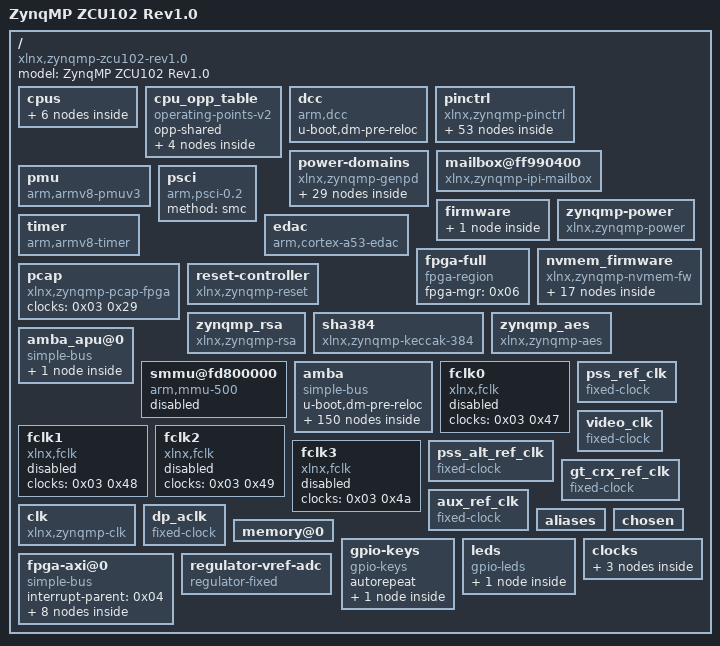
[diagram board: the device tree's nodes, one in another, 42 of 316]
/dts-v1/;

/ {
	compatible = "xlnx,zynqmp-zcu102-rev1.0\0xlnx,zynqmp-zcu102\0xlnx,zynqmp";
	#address-cells = <0x02>;
	#size-cells = <0x02>;
	model = "ZynqMP ZCU102 Rev1.0";

	cpus {
		#address-cells = <0x01>;
		#size-cells = <0x00>;

		cpu@0 {
			compatible = "arm,cortex-a53\0arm,armv8";
			device_type = "cpu";
			enable-method = "psci";
			operating-points-v2 = <0x01>;
			reg = <0x00>;
			cpu-idle-states = <0x02>;
			clocks = <0x03 0x0a>;
		};

		cpu@1 {
			compatible = "arm,cortex-a53\0arm,armv8";
			device_type = "cpu";
			enable-method = "psci";
			reg = <0x01>;
			operating-points-v2 = <0x01>;
			cpu-idle-states = <0x02>;
		};

		cpu@2 {
			compatible = "arm,cortex-a53\0arm,armv8";
			device_type = "cpu";
			enable-method = "psci";
			reg = <0x02>;
			operating-points-v2 = <0x01>;
			cpu-idle-states = <0x02>;
		};

		cpu@3 {
			compatible = "arm,cortex-a53\0arm,armv8";
			device_type = "cpu";
			enable-method = "psci";
			reg = <0x03>;
			operating-points-v2 = <0x01>;
			cpu-idle-states = <0x02>;
		};

		idle-states {
			entry-method = "arm,psci";

			cpu-sleep-0 {
				compatible = "arm,idle-state";
				arm,psci-suspend-param = <0x40000000>;
				local-timer-stop;
				entry-latency-us = <0x12c>;
				exit-latency-us = <0x258>;
				min-residency-us = <0x2710>;
				linux,phandle = <0x02>;
				phandle = <0x02>;
			};
		};
	};

	cpu_opp_table {
		compatible = "operating-points-v2";
		opp-shared;
		linux,phandle = <0x01>;
		phandle = <0x01>;

		opp00 {
			opp-hz = <0x00 0x47868bf4>;
			opp-microvolt = <0xf4240>;
			clock-latency-ns = <0x7a120>;
		};

		opp01 {
			opp-hz = <0x00 0x23c345fa>;
			opp-microvolt = <0xf4240>;
			clock-latency-ns = <0x7a120>;
		};

		opp02 {
			opp-hz = <0x00 0x17d783fc>;
			opp-microvolt = <0xf4240>;
			clock-latency-ns = <0x7a120>;
		};

		opp03 {
			opp-hz = <0x00 0x11e1a2fd>;
			opp-microvolt = <0xf4240>;
			clock-latency-ns = <0x7a120>;
		};
	};

	dcc {
		compatible = "arm,dcc";
		status = "okay";
		u-boot,dm-pre-reloc;
	};

	pinctrl {
		compatible = "xlnx,zynqmp-pinctrl";
		status = "okay";

		i2c0-default {
			linux,phandle = <0x18>;
			phandle = <0x18>;

			mux {
				groups = "i2c0_3_grp";
				function = "i2c0";
			};

			conf {
				groups = "i2c0_3_grp";
				bias-pull-up;
				slew-rate = <0x01>;
				io-standard = <0x01>;
			};
		};

		i2c0-gpio {
			linux,phandle = <0x19>;
			phandle = <0x19>;

			mux {
				groups = "gpio0_14_grp\0gpio0_15_grp";
				function = "gpio0";
			};

			conf {
				groups = "gpio0_14_grp\0gpio0_15_grp";
				slew-rate = <0x01>;
				io-standard = <0x01>;
			};
		};

		i2c1-default {
			linux,phandle = <0x1c>;
			phandle = <0x1c>;

			mux {
				groups = "i2c1_4_grp";
				function = "i2c1";
			};

			conf {
				groups = "i2c1_4_grp";
				bias-pull-up;
				slew-rate = <0x01>;
				io-standard = <0x01>;
			};
		};

		i2c1-gpio {
			linux,phandle = <0x1d>;
			phandle = <0x1d>;

			mux {
				groups = "gpio0_16_grp\0gpio0_17_grp";
				function = "gpio0";
			};

			conf {
				groups = "gpio0_16_grp\0gpio0_17_grp";
				slew-rate = <0x01>;
				io-standard = <0x01>;
			};
		};

		uart0-default {
			linux,phandle = <0x32>;
			phandle = <0x32>;

			mux {
				groups = "uart0_4_grp";
				function = "uart0";
			};

			conf {
				groups = "uart0_4_grp";
				slew-rate = <0x01>;
				io-standard = <0x01>;
			};

			conf-rx {
				pins = "MIO18";
				bias-high-impedance;
			};

			conf-tx {
				pins = "MIO19";
				bias-disable;
			};
		};

		uart1-default {
			linux,phandle = <0x34>;
			phandle = <0x34>;

			mux {
				groups = "uart1_5_grp";
				function = "uart1";
			};

			conf {
				groups = "uart1_5_grp";
				slew-rate = <0x01>;
				io-standard = <0x01>;
			};

			conf-rx {
				pins = "MIO21";
				bias-high-impedance;
			};

			conf-tx {
				pins = "MIO20";
				bias-disable;
			};
		};

		usb0-default {
			linux,phandle = <0x36>;
			phandle = <0x36>;

			mux {
				groups = "usb0_0_grp";
				function = "usb0";
			};

			conf {
				groups = "usb0_0_grp";
				slew-rate = <0x01>;
				io-standard = <0x01>;
			};

			conf-rx {
				pins = "MIO52\0MIO53\0MIO55";
				bias-high-impedance;
			};

			conf-tx {
				pins = "MIO54\0MIO56\0MIO57\0MIO58\0MIO59\0MIO60\0MIO61\0MIO62\0MIO63";
				bias-disable;
			};
		};

		gem3-default {
			linux,phandle = <0x14>;
			phandle = <0x14>;

			mux {
				function = "ethernet3";
				groups = "ethernet3_0_grp";
			};

			conf {
				groups = "ethernet3_0_grp";
				slew-rate = <0x01>;
				io-standard = <0x01>;
			};

			conf-rx {
				pins = "MIO70\0MIO71\0MIO72\0MIO73\0MIO74\0MIO75";
				bias-high-impedance;
				low-power-disable;
			};

			conf-tx {
				pins = "MIO64\0MIO65\0MIO66\0MIO67\0MIO68\0MIO69";
				bias-disable;
				low-power-enable;
			};

			mux-mdio {
				function = "mdio3";
				groups = "mdio3_0_grp";
			};

			conf-mdio {
				groups = "mdio3_0_grp";
				slew-rate = <0x01>;
				io-standard = <0x01>;
				bias-disable;
			};
		};

		can1-default {
			linux,phandle = <0x09>;
			phandle = <0x09>;

			mux {
				function = "can1";
				groups = "can1_6_grp";
			};

			conf {
				groups = "can1_6_grp";
				slew-rate = <0x01>;
				io-standard = <0x01>;
			};

			conf-rx {
				pins = "MIO25";
				bias-high-impedance;
			};

			conf-tx {
				pins = "MIO24";
				bias-disable;
			};
		};

		sdhci1-default {
			linux,phandle = <0x28>;
			phandle = <0x28>;

			mux {
				groups = "sdio1_0_grp";
				function = "sdio1";
			};

			conf {
				groups = "sdio1_0_grp";
				slew-rate = <0x01>;
				io-standard = <0x01>;
				bias-disable;
			};

			mux-cd {
				groups = "sdio1_cd_0_grp";
				function = "sdio1_cd";
			};

			conf-cd {
				groups = "sdio1_cd_0_grp";
				bias-high-impedance;
				bias-pull-up;
				slew-rate = <0x01>;
				io-standard = <0x01>;
			};

			mux-wp {
				groups = "sdio1_wp_0_grp";
				function = "sdio1_wp";
			};

			conf-wp {
				groups = "sdio1_wp_0_grp";
				bias-high-impedance;
				bias-pull-up;
				slew-rate = <0x01>;
				io-standard = <0x01>;
			};
		};

		gpio-default {
			linux,phandle = <0x16>;
			phandle = <0x16>;

			mux-sw {
				function = "gpio0";
				groups = "gpio0_22_grp\0gpio0_23_grp";
			};

			conf-sw {
				groups = "gpio0_22_grp\0gpio0_23_grp";
				slew-rate = <0x01>;
				io-standard = <0x01>;
			};

			mux-msp {
				function = "gpio0";
				groups = "gpio0_13_grp\0gpio0_38_grp";
			};

			conf-msp {
				groups = "gpio0_13_grp\0gpio0_38_grp";
				slew-rate = <0x01>;
				io-standard = <0x01>;
			};

			conf-pull-up {
				pins = "MIO22\0MIO23";
				bias-pull-up;
			};

			conf-pull-none {
				pins = "MIO13\0MIO38";
				bias-disable;
			};
		};
	};

	power-domains {
		compatible = "xlnx,zynqmp-genpd";

		pd-usb0 {
			#power-domain-cells = <0x00>;
			pd-id = <0x16>;
			linux,phandle = <0x35>;
			phandle = <0x35>;
		};

		pd-usb1 {
			#power-domain-cells = <0x00>;
			pd-id = <0x17>;
			linux,phandle = <0x38>;
			phandle = <0x38>;
		};

		pd-sata {
			#power-domain-cells = <0x00>;
			pd-id = <0x1c>;
			linux,phandle = <0x24>;
			phandle = <0x24>;
		};

		pd-spi0 {
			#power-domain-cells = <0x00>;
			pd-id = <0x23>;
			linux,phandle = <0x29>;
			phandle = <0x29>;
		};

		pd-spi1 {
			#power-domain-cells = <0x00>;
			pd-id = <0x24>;
			linux,phandle = <0x2c>;
			phandle = <0x2c>;
		};

		pd-uart0 {
			#power-domain-cells = <0x00>;
			pd-id = <0x21>;
			linux,phandle = <0x31>;
			phandle = <0x31>;
		};

		pd-uart1 {
			#power-domain-cells = <0x00>;
			pd-id = <0x22>;
			linux,phandle = <0x33>;
			phandle = <0x33>;
		};

		pd-eth0 {
			#power-domain-cells = <0x00>;
			pd-id = <0x1d>;
			linux,phandle = <0x0f>;
			phandle = <0x0f>;
		};

		pd-eth1 {
			#power-domain-cells = <0x00>;
			pd-id = <0x1e>;
			linux,phandle = <0x10>;
			phandle = <0x10>;
		};

		pd-eth2 {
			#power-domain-cells = <0x00>;
			pd-id = <0x1f>;
			linux,phandle = <0x11>;
			phandle = <0x11>;
		};

		pd-eth3 {
			#power-domain-cells = <0x00>;
			pd-id = <0x20>;
			linux,phandle = <0x12>;
			phandle = <0x12>;
		};

		pd-i2c0 {
			#power-domain-cells = <0x00>;
			pd-id = <0x25>;
			linux,phandle = <0x17>;
			phandle = <0x17>;
		};

		pd-i2c1 {
			#power-domain-cells = <0x00>;
			pd-id = <0x26>;
			linux,phandle = <0x1b>;
			phandle = <0x1b>;
		};

		pd-dp {
			#power-domain-cells = <0x00>;
			pd-id = <0x29>;
			linux,phandle = <0x39>;
			phandle = <0x39>;
		};

		pd-gdma {
			#power-domain-cells = <0x00>;
			pd-id = <0x2a>;
			linux,phandle = <0x0b>;
			phandle = <0x0b>;
		};

		pd-adma {
			#power-domain-cells = <0x00>;
			pd-id = <0x2b>;
			linux,phandle = <0x0d>;
			phandle = <0x0d>;
		};

		pd-ttc0 {
			#power-domain-cells = <0x00>;
			pd-id = <0x18>;
			linux,phandle = <0x2d>;
			phandle = <0x2d>;
		};

		pd-ttc1 {
			#power-domain-cells = <0x00>;
			pd-id = <0x19>;
			linux,phandle = <0x2e>;
			phandle = <0x2e>;
		};

		pd-ttc2 {
			#power-domain-cells = <0x00>;
			pd-id = <0x1a>;
			linux,phandle = <0x2f>;
			phandle = <0x2f>;
		};

		pd-ttc3 {
			#power-domain-cells = <0x00>;
			pd-id = <0x1b>;
			linux,phandle = <0x30>;
			phandle = <0x30>;
		};

		pd-sd0 {
			#power-domain-cells = <0x00>;
			pd-id = <0x27>;
			linux,phandle = <0x26>;
			phandle = <0x26>;
		};

		pd-sd1 {
			#power-domain-cells = <0x00>;
			pd-id = <0x28>;
			linux,phandle = <0x27>;
			phandle = <0x27>;
		};

		pd-nand {
			#power-domain-cells = <0x00>;
			pd-id = <0x2c>;
			linux,phandle = <0x0e>;
			phandle = <0x0e>;
		};

		pd-qspi {
			#power-domain-cells = <0x00>;
			pd-id = <0x2d>;
			linux,phandle = <0x21>;
			phandle = <0x21>;
		};

		pd-gpio {
			#power-domain-cells = <0x00>;
			pd-id = <0x2e>;
			linux,phandle = <0x15>;
			phandle = <0x15>;
		};

		pd-can0 {
			#power-domain-cells = <0x00>;
			pd-id = <0x2f>;
			linux,phandle = <0x07>;
			phandle = <0x07>;
		};

		pd-can1 {
			#power-domain-cells = <0x00>;
			pd-id = <0x30>;
			linux,phandle = <0x08>;
			phandle = <0x08>;
		};

		pd-pcie {
			#power-domain-cells = <0x00>;
			pd-id = <0x3b>;
			linux,phandle = <0x20>;
			phandle = <0x20>;
		};

		pd-gpu {
			#power-domain-cells = <0x00>;
			pd-id = <0x3a 0x14 0x15>;
			linux,phandle = <0x0c>;
			phandle = <0x0c>;
		};
	};

	mailbox@ff990400 {
		compatible = "xlnx,zynqmp-ipi-mailbox";
		reg = <0x00 0xff9905c0 0x00 0x20 0x00 0xff9905e0 0x00 0x20 0x00 0xff990e80 0x00 0x20 0x00 0xff990ea0 0x00 0x20>;
		reg-names = "local_request_region\0local_response_region\0remote_request_region\0remote_response_region";
		#mbox-cells = <0x01>;
		xlnx,ipi-ids = <0x00 0x04>;
		interrupt-parent = <0x04>;
		interrupts = <0x00 0x23 0x04>;
		linux,phandle = <0x05>;
		phandle = <0x05>;
	};

	pmu {
		compatible = "arm,armv8-pmuv3";
		interrupt-parent = <0x04>;
		interrupts = <0x00 0x8f 0x04 0x00 0x90 0x04 0x00 0x91 0x04 0x00 0x92 0x04>;
	};

	psci {
		compatible = "arm,psci-0.2";
		method = "smc";
	};

	firmware {

		zynqmp-firmware {
			compatible = "xlnx,zynqmp-firmware";
			method = "smc";
		};
	};

	zynqmp-power {
		compatible = "xlnx,zynqmp-power";
		mboxes = <0x05 0x00 0x05 0x01>;
		mbox-names = "tx\0rx";
	};

	timer {
		compatible = "arm,armv8-timer";
		interrupt-parent = <0x04>;
		interrupts = <0x01 0x0d 0xf08 0x01 0x0e 0xf08 0x01 0x0b 0xf08 0x01 0x0a 0xf08>;
	};

	edac {
		compatible = "arm,cortex-a53-edac";
	};

	fpga-full {
		compatible = "fpga-region";
		fpga-mgr = <0x06>;
		#address-cells = <0x02>;
		#size-cells = <0x02>;
	};

	nvmem_firmware {
		compatible = "xlnx,zynqmp-nvmem-fw";
		#address-cells = <0x01>;
		#size-cells = <0x01>;

		soc_revision@0 {
			reg = <0x00 0x04>;
			linux,phandle = <0x22>;
			phandle = <0x22>;
		};

		efuse_dna@c {
			reg = <0x0c 0x0c>;
		};

		efuse_usr0@20 {
			reg = <0x20 0x04>;
		};

		efuse_usr1@24 {
			reg = <0x24 0x04>;
		};

		efuse_usr2@28 {
			reg = <0x28 0x04>;
		};

		efuse_usr3@2c {
			reg = <0x2c 0x04>;
		};

		efuse_usr4@30 {
			reg = <0x30 0x04>;
		};

		efuse_usr5@34 {
			reg = <0x34 0x04>;
		};

		efuse_usr6@38 {
			reg = <0x38 0x04>;
		};

		efuse_usr7@3c {
			reg = <0x3c 0x04>;
		};

		efuse_miscusr@40 {
			reg = <0x40 0x04>;
		};

		efuse_chash@50 {
			reg = <0x50 0x04>;
		};

		efuse_pufmisc@54 {
			reg = <0x54 0x04>;
		};

		efuse_sec@58 {
			reg = <0x58 0x04>;
		};

		efuse_spkid@5c {
			reg = <0x5c 0x04>;
		};

		efuse_ppk0hash@a0 {
			reg = <0xa0 0x30>;
		};

		efuse_ppk1hash@d0 {
			reg = <0xd0 0x30>;
		};
	};

	pcap {
		compatible = "xlnx,zynqmp-pcap-fpga";
		clock-names = "ref_clk";
		clocks = <0x03 0x29>;
		linux,phandle = <0x06>;
		phandle = <0x06>;
	};

	reset-controller {
		compatible = "xlnx,zynqmp-reset";
		#reset-cells = <0x01>;
		linux,phandle = <0x23>;
		phandle = <0x23>;
	};

	zynqmp_rsa {
		compatible = "xlnx,zynqmp-rsa";
	};

	sha384 {
		compatible = "xlnx,zynqmp-keccak-384";
	};

	zynqmp_aes {
		compatible = "xlnx,zynqmp-aes";
	};

	amba_apu@0 {
		compatible = "simple-bus";
		#address-cells = <0x02>;
		#size-cells = <0x01>;
		ranges = <0x00 0x00 0x00 0x00 0xffffffff>;

		interrupt-controller@f9010000 {
			compatible = "arm,gic-400\0arm,cortex-a15-gic";
			#interrupt-cells = <0x03>;
			reg = <0x00 0xf9010000 0x10000 0x00 0xf9020000 0x20000 0x00 0xf9040000 0x20000 0x00 0xf9060000 0x20000>;
			interrupt-controller;
			interrupt-parent = <0x04>;
			interrupts = <0x01 0x09 0xf04>;
			linux,phandle = <0x04>;
			phandle = <0x04>;
		};
	};

	smmu@fd800000 {
		compatible = "arm,mmu-500";
		reg = <0x00 0xfd800000 0x00 0x20000>;
		#iommu-cells = <0x01>;
		status = "disabled";
		#global-interrupts = <0x01>;
		interrupt-parent = <0x04>;
		interrupts = <0x00 0x9b 0x04 0x00 0x9b 0x04 0x00 0x9b 0x04 0x00 0x9b 0x04 0x00 0x9b 0x04 0x00 0x9b 0x04 0x00 0x9b 0x04 0x00 0x9b 0x04 0x00 0x9b 0x04 0x00 0x9b 0x04 0x00 0x9b 0x04 0x00 0x9b 0x04 0x00 0x9b 0x04 0x00 0x9b 0x04 0x00 0x9b 0x04 0x00 0x9b 0x04 0x00 0x9b 0x04>;
		linux,phandle = <0x0a>;
		phandle = <0x0a>;
	};

	amba {
		compatible = "simple-bus";
		u-boot,dm-pre-reloc;
		#address-cells = <0x02>;
		#size-cells = <0x02>;
		ranges;

		can@ff060000 {
			compatible = "xlnx,zynq-can-1.0";
			status = "disabled";
			clock-names = "can_clk\0pclk";
			reg = <0x00 0xff060000 0x00 0x1000>;
			interrupts = <0x00 0x17 0x04>;
			interrupt-parent = <0x04>;
			tx-fifo-depth = <0x40>;
			rx-fifo-depth = <0x40>;
			power-domains = <0x07>;
			clocks = <0x03 0x3f 0x03 0x1f>;
		};

		can@ff070000 {
			compatible = "xlnx,zynq-can-1.0";
			status = "okay";
			clock-names = "can_clk\0pclk";
			reg = <0x00 0xff070000 0x00 0x1000>;
			interrupts = <0x00 0x18 0x04>;
			interrupt-parent = <0x04>;
			tx-fifo-depth = <0x40>;
			rx-fifo-depth = <0x40>;
			power-domains = <0x08>;
			clocks = <0x03 0x40 0x03 0x1f>;
			pinctrl-names = "default";
			pinctrl-0 = <0x09>;
		};

		cci@fd6e0000 {
			compatible = "arm,cci-400";
			reg = <0x00 0xfd6e0000 0x00 0x9000>;
			ranges = <0x00 0x00 0xfd6e0000 0x10000>;
			#address-cells = <0x01>;
			#size-cells = <0x01>;

			pmu@9000 {
				compatible = "arm,cci-400-pmu,r1";
				reg = <0x9000 0x5000>;
				interrupt-parent = <0x04>;
				interrupts = <0x00 0x7b 0x04 0x00 0x7b 0x04 0x00 0x7b 0x04 0x00 0x7b 0x04 0x00 0x7b 0x04>;
			};
		};

		dma@fd500000 {
			status = "okay";
			compatible = "xlnx,zynqmp-dma-1.0";
			reg = <0x00 0xfd500000 0x00 0x1000>;
			interrupt-parent = <0x04>;
			interrupts = <0x00 0x7c 0x04>;
			clock-names = "clk_main\0clk_apb";
			xlnx,bus-width = <0x80>;
			#stream-id-cells = <0x01>;
			iommus = <0x0a 0x14e8>;
			power-domains = <0x0b>;
			clocks = <0x03 0x13 0x03 0x1f>;
		};

		dma@fd510000 {
			status = "okay";
			compatible = "xlnx,zynqmp-dma-1.0";
			reg = <0x00 0xfd510000 0x00 0x1000>;
			interrupt-parent = <0x04>;
			interrupts = <0x00 0x7d 0x04>;
			clock-names = "clk_main\0clk_apb";
			xlnx,bus-width = <0x80>;
			#stream-id-cells = <0x01>;
			iommus = <0x0a 0x14e9>;
			power-domains = <0x0b>;
			clocks = <0x03 0x13 0x03 0x1f>;
		};

		dma@fd520000 {
			status = "okay";
			compatible = "xlnx,zynqmp-dma-1.0";
			reg = <0x00 0xfd520000 0x00 0x1000>;
			interrupt-parent = <0x04>;
			interrupts = <0x00 0x7e 0x04>;
			clock-names = "clk_main\0clk_apb";
			xlnx,bus-width = <0x80>;
			#stream-id-cells = <0x01>;
			iommus = <0x0a 0x14ea>;
			power-domains = <0x0b>;
			clocks = <0x03 0x13 0x03 0x1f>;
		};

		dma@fd530000 {
			status = "okay";
			compatible = "xlnx,zynqmp-dma-1.0";
			reg = <0x00 0xfd530000 0x00 0x1000>;
			interrupt-parent = <0x04>;
			interrupts = <0x00 0x7f 0x04>;
			clock-names = "clk_main\0clk_apb";
			xlnx,bus-width = <0x80>;
			#stream-id-cells = <0x01>;
			iommus = <0x0a 0x14eb>;
			power-domains = <0x0b>;
			clocks = <0x03 0x13 0x03 0x1f>;
		};

		dma@fd540000 {
			status = "okay";
			compatible = "xlnx,zynqmp-dma-1.0";
			reg = <0x00 0xfd540000 0x00 0x1000>;
			interrupt-parent = <0x04>;
			interrupts = <0x00 0x80 0x04>;
			clock-names = "clk_main\0clk_apb";
			xlnx,bus-width = <0x80>;
			#stream-id-cells = <0x01>;
			iommus = <0x0a 0x14ec>;
			power-domains = <0x0b>;
			clocks = <0x03 0x13 0x03 0x1f>;
		};

		dma@fd550000 {
			status = "okay";
			compatible = "xlnx,zynqmp-dma-1.0";
			reg = <0x00 0xfd550000 0x00 0x1000>;
			interrupt-parent = <0x04>;
			interrupts = <0x00 0x81 0x04>;
			clock-names = "clk_main\0clk_apb";
			xlnx,bus-width = <0x80>;
			#stream-id-cells = <0x01>;
			iommus = <0x0a 0x14ed>;
			power-domains = <0x0b>;
			clocks = <0x03 0x13 0x03 0x1f>;
		};

		dma@fd560000 {
			status = "okay";
			compatible = "xlnx,zynqmp-dma-1.0";
			reg = <0x00 0xfd560000 0x00 0x1000>;
			interrupt-parent = <0x04>;
			interrupts = <0x00 0x82 0x04>;
			clock-names = "clk_main\0clk_apb";
			xlnx,bus-width = <0x80>;
			#stream-id-cells = <0x01>;
			iommus = <0x0a 0x14ee>;
			power-domains = <0x0b>;
			clocks = <0x03 0x13 0x03 0x1f>;
		};

		dma@fd570000 {
			status = "okay";
			compatible = "xlnx,zynqmp-dma-1.0";
			reg = <0x00 0xfd570000 0x00 0x1000>;
			interrupt-parent = <0x04>;
			interrupts = <0x00 0x83 0x04>;
			clock-names = "clk_main\0clk_apb";
			xlnx,bus-width = <0x80>;
			#stream-id-cells = <0x01>;
			iommus = <0x0a 0x14ef>;
			power-domains = <0x0b>;
			clocks = <0x03 0x13 0x03 0x1f>;
		};

		gpu@fd4b0000 {
			status = "okay";
			compatible = "arm,mali-400\0arm,mali-utgard";
			reg = <0x00 0xfd4b0000 0x00 0x10000>;
			interrupt-parent = <0x04>;
			interrupts = <0x00 0x84 0x04 0x00 0x84 0x04 0x00 0x84 0x04 0x00 0x84 0x04 0x00 0x84 0x04 0x00 0x84 0x04>;
			interrupt-names = "IRQGP\0IRQGPMMU\0IRQPP0\0IRQPPMMU0\0IRQPP1\0IRQPPMMU1";
			clock-names = "gpu\0gpu_pp0\0gpu_pp1";
			power-domains = <0x0c>;
			clocks = <0x03 0x18 0x03 0x19 0x03 0x1a>;
		};

		dma@ffa80000 {
			status = "disabled";
			compatible = "xlnx,zynqmp-dma-1.0";
			reg = <0x00 0xffa80000 0x00 0x1000>;
			interrupt-parent = <0x04>;
			interrupts = <0x00 0x4d 0x04>;
			clock-names = "clk_main\0clk_apb";
			xlnx,bus-width = <0x40>;
			#stream-id-cells = <0x01>;
			power-domains = <0x0d>;
			clocks = <0x03 0x44 0x03 0x1f>;
		};

		dma@ffa90000 {
			status = "disabled";
			compatible = "xlnx,zynqmp-dma-1.0";
			reg = <0x00 0xffa90000 0x00 0x1000>;
			interrupt-parent = <0x04>;
			interrupts = <0x00 0x4e 0x04>;
			clock-names = "clk_main\0clk_apb";
			xlnx,bus-width = <0x40>;
			#stream-id-cells = <0x01>;
			power-domains = <0x0d>;
			clocks = <0x03 0x44 0x03 0x1f>;
		};

		dma@ffaa0000 {
			status = "disabled";
			compatible = "xlnx,zynqmp-dma-1.0";
			reg = <0x00 0xffaa0000 0x00 0x1000>;
			interrupt-parent = <0x04>;
			interrupts = <0x00 0x4f 0x04>;
			clock-names = "clk_main\0clk_apb";
			xlnx,bus-width = <0x40>;
			#stream-id-cells = <0x01>;
			power-domains = <0x0d>;
			clocks = <0x03 0x44 0x03 0x1f>;
		};

		dma@ffab0000 {
			status = "disabled";
			compatible = "xlnx,zynqmp-dma-1.0";
			reg = <0x00 0xffab0000 0x00 0x1000>;
			interrupt-parent = <0x04>;
			interrupts = <0x00 0x50 0x04>;
			clock-names = "clk_main\0clk_apb";
			xlnx,bus-width = <0x40>;
			#stream-id-cells = <0x01>;
			power-domains = <0x0d>;
			clocks = <0x03 0x44 0x03 0x1f>;
		};

		dma@ffac0000 {
			status = "disabled";
			compatible = "xlnx,zynqmp-dma-1.0";
			reg = <0x00 0xffac0000 0x00 0x1000>;
			interrupt-parent = <0x04>;
			interrupts = <0x00 0x51 0x04>;
			clock-names = "clk_main\0clk_apb";
			xlnx,bus-width = <0x40>;
			#stream-id-cells = <0x01>;
			power-domains = <0x0d>;
			clocks = <0x03 0x44 0x03 0x1f>;
		};

		dma@ffad0000 {
			status = "disabled";
			compatible = "xlnx,zynqmp-dma-1.0";
			reg = <0x00 0xffad0000 0x00 0x1000>;
			interrupt-parent = <0x04>;
			interrupts = <0x00 0x52 0x04>;
			clock-names = "clk_main\0clk_apb";
			xlnx,bus-width = <0x40>;
			#stream-id-cells = <0x01>;
			power-domains = <0x0d>;
			clocks = <0x03 0x44 0x03 0x1f>;
		};

		dma@ffae0000 {
			status = "disabled";
			compatible = "xlnx,zynqmp-dma-1.0";
			reg = <0x00 0xffae0000 0x00 0x1000>;
			interrupt-parent = <0x04>;
			interrupts = <0x00 0x53 0x04>;
			clock-names = "clk_main\0clk_apb";
			xlnx,bus-width = <0x40>;
			#stream-id-cells = <0x01>;
			power-domains = <0x0d>;
			clocks = <0x03 0x44 0x03 0x1f>;
		};

		dma@ffaf0000 {
			status = "disabled";
			compatible = "xlnx,zynqmp-dma-1.0";
			reg = <0x00 0xffaf0000 0x00 0x1000>;
			interrupt-parent = <0x04>;
			interrupts = <0x00 0x54 0x04>;
			clock-names = "clk_main\0clk_apb";
			xlnx,bus-width = <0x40>;
			#stream-id-cells = <0x01>;
			power-domains = <0x0d>;
			clocks = <0x03 0x44 0x03 0x1f>;
		};

		memory-controller@fd070000 {
			compatible = "xlnx,zynqmp-ddrc-2.40a";
			reg = <0x00 0xfd070000 0x00 0x30000>;
			interrupt-parent = <0x04>;
			interrupts = <0x00 0x70 0x04>;
		};

		nand@ff100000 {
			compatible = "arasan,nfc-v3p10";
			status = "disabled";
			reg = <0x00 0xff100000 0x00 0x1000>;
			clock-names = "clk_sys\0clk_flash";
			interrupt-parent = <0x04>;
			interrupts = <0x00 0x0e 0x04>;
			#address-cells = <0x01>;
			#size-cells = <0x00>;
			#stream-id-cells = <0x01>;
			iommus = <0x0a 0x872>;
			power-domains = <0x0e>;
			clocks = <0x03 0x3c 0x03 0x1f>;
		};

		ethernet@ff0b0000 {
			compatible = "cdns,zynqmp-gem\0cdns,gem";
			status = "disabled";
			interrupt-parent = <0x04>;
			interrupts = <0x00 0x39 0x04 0x00 0x39 0x04>;
			reg = <0x00 0xff0b0000 0x00 0x1000>;
			clock-names = "pclk\0hclk\0tx_clk\0rx_clk\0tsu_clk";
			#address-cells = <0x01>;
			#size-cells = <0x00>;
			#stream-id-cells = <0x01>;
			iommus = <0x0a 0x874>;
			power-domains = <0x0f>;
			clocks = <0x03 0x1f 0x03 0x68 0x03 0x2d 0x03 0x31 0x03 0x2c>;
		};

		ethernet@ff0c0000 {
			compatible = "cdns,zynqmp-gem\0cdns,gem";
			status = "disabled";
			interrupt-parent = <0x04>;
			interrupts = <0x00 0x3b 0x04 0x00 0x3b 0x04>;
			reg = <0x00 0xff0c0000 0x00 0x1000>;
			clock-names = "pclk\0hclk\0tx_clk\0rx_clk\0tsu_clk";
			#address-cells = <0x01>;
			#size-cells = <0x00>;
			#stream-id-cells = <0x01>;
			iommus = <0x0a 0x875>;
			power-domains = <0x10>;
			clocks = <0x03 0x1f 0x03 0x69 0x03 0x2e 0x03 0x32 0x03 0x2c>;
		};

		ethernet@ff0d0000 {
			compatible = "cdns,zynqmp-gem\0cdns,gem";
			status = "disabled";
			interrupt-parent = <0x04>;
			interrupts = <0x00 0x3d 0x04 0x00 0x3d 0x04>;
			reg = <0x00 0xff0d0000 0x00 0x1000>;
			clock-names = "pclk\0hclk\0tx_clk\0rx_clk\0tsu_clk";
			#address-cells = <0x01>;
			#size-cells = <0x00>;
			#stream-id-cells = <0x01>;
			iommus = <0x0a 0x876>;
			power-domains = <0x11>;
			clocks = <0x03 0x1f 0x03 0x6a 0x03 0x2f 0x03 0x33 0x03 0x2c>;
		};

		ethernet@ff0e0000 {
			compatible = "cdns,zynqmp-gem\0cdns,gem";
			status = "okay";
			interrupt-parent = <0x04>;
			interrupts = <0x00 0x3f 0x04 0x00 0x3f 0x04>;
			reg = <0x00 0xff0e0000 0x00 0x1000>;
			clock-names = "pclk\0hclk\0tx_clk\0rx_clk\0tsu_clk";
			#address-cells = <0x01>;
			#size-cells = <0x00>;
			#stream-id-cells = <0x01>;
			iommus = <0x0a 0x877>;
			power-domains = <0x12>;
			clocks = <0x03 0x1f 0x03 0x6b 0x03 0x30 0x03 0x34 0x03 0x2c>;
			phy-handle = <0x13>;
			phy-mode = "rgmii-id";
			pinctrl-names = "default";
			pinctrl-0 = <0x14>;

			phy@c {
				reg = <0x0c>;
				ti,rx-internal-delay = <0x08>;
				ti,tx-internal-delay = <0x0a>;
				ti,fifo-depth = <0x01>;
				ti,rxctrl-strap-worka;
				linux,phandle = <0x13>;
				phandle = <0x13>;
			};
		};

		gpio@ff0a0000 {
			compatible = "xlnx,zynqmp-gpio-1.0";
			status = "okay";
			#gpio-cells = <0x02>;
			interrupt-parent = <0x04>;
			interrupts = <0x00 0x10 0x04>;
			interrupt-controller;
			#interrupt-cells = <0x02>;
			reg = <0x00 0xff0a0000 0x00 0x1000>;
			gpio-controller;
			power-domains = <0x15>;
			clocks = <0x03 0x1f>;
			pinctrl-names = "default";
			pinctrl-0 = <0x16>;
			linux,phandle = <0x1a>;
			phandle = <0x1a>;

			gpio_clk_en_n {
				gpio-hog;
				gpios = <0x76 0x00>;
				output-low;
				line-name = "gpio-clk-en-n";
			};
		};

		i2c@ff020000 {
			compatible = "cdns,i2c-r1p14\0cdns,i2c-r1p10";
			status = "okay";
			interrupt-parent = <0x04>;
			interrupts = <0x00 0x11 0x04>;
			reg = <0x00 0xff020000 0x00 0x1000>;
			#address-cells = <0x01>;
			#size-cells = <0x00>;
			power-domains = <0x17>;
			clocks = <0x03 0x3d>;
			clock-frequency = <0x61a80>;
			pinctrl-names = "default\0gpio";
			pinctrl-0 = <0x18>;
			pinctrl-1 = <0x19>;
			scl-gpios = <0x1a 0x0e 0x00>;
			sda-gpios = <0x1a 0x0f 0x00>;

			gpio@20 {
				compatible = "ti,tca6416";
				reg = <0x20>;
				gpio-controller;
				#gpio-cells = <0x02>;

				gtr_sel0 {
					gpio-hog;
					gpios = <0x00 0x00>;
					output-low;
					line-name = "sel0";
				};

				gtr_sel1 {
					gpio-hog;
					gpios = <0x01 0x00>;
					output-high;
					line-name = "sel1";
				};

				gtr_sel2 {
					gpio-hog;
					gpios = <0x02 0x00>;
					output-high;
					line-name = "sel2";
				};

				gtr_sel3 {
					gpio-hog;
					gpios = <0x03 0x00>;
					output-high;
					line-name = "sel3";
				};
			};

			gpio@21 {
				compatible = "ti,tca6416";
				reg = <0x21>;
				gpio-controller;
				#gpio-cells = <0x02>;
			};

			i2c-mux@75 {
				compatible = "nxp,pca9544";
				#address-cells = <0x01>;
				#size-cells = <0x00>;
				reg = <0x75>;

				i2c@0 {
					#address-cells = <0x01>;
					#size-cells = <0x00>;
					reg = <0x00>;

					ina226@40 {
						compatible = "ti,ina226";
						reg = <0x40>;
						shunt-resistor = <0x1388>;
					};

					ina226@41 {
						compatible = "ti,ina226";
						reg = <0x41>;
						shunt-resistor = <0x1388>;
					};

					ina226@42 {
						compatible = "ti,ina226";
						reg = <0x42>;
						shunt-resistor = <0x1388>;
					};

					ina226@43 {
						compatible = "ti,ina226";
						reg = <0x43>;
						shunt-resistor = <0x1388>;
					};

					ina226@44 {
						compatible = "ti,ina226";
						reg = <0x44>;
						shunt-resistor = <0x1388>;
					};

					ina226@45 {
						compatible = "ti,ina226";
						reg = <0x45>;
						shunt-resistor = <0x1388>;
					};

					ina226@46 {
						compatible = "ti,ina226";
						reg = <0x46>;
						shunt-resistor = <0x1388>;
					};

					ina226@47 {
						compatible = "ti,ina226";
						reg = <0x47>;
						shunt-resistor = <0x1388>;
					};

					ina226@4a {
						compatible = "ti,ina226";
						reg = <0x4a>;
						shunt-resistor = <0x1388>;
					};

					ina226@4b {
						compatible = "ti,ina226";
						reg = <0x4b>;
						shunt-resistor = <0x1388>;
					};
				};

				i2c@1 {
					#address-cells = <0x01>;
					#size-cells = <0x00>;
					reg = <0x01>;

					ina226@40 {
						compatible = "ti,ina226";
						reg = <0x40>;
						shunt-resistor = <0x7d0>;
					};

					ina226@41 {
						compatible = "ti,ina226";
						reg = <0x41>;
						shunt-resistor = <0x1388>;
					};

					ina226@42 {
						compatible = "ti,ina226";
						reg = <0x42>;
						shunt-resistor = <0x1388>;
					};

					ina226@43 {
						compatible = "ti,ina226";
						reg = <0x43>;
						shunt-resistor = <0x1388>;
					};

					ina226@44 {
						compatible = "ti,ina226";
						reg = <0x44>;
						shunt-resistor = <0x1388>;
					};

					ina226@45 {
						compatible = "ti,ina226";
						reg = <0x45>;
						shunt-resistor = <0x1388>;
					};

					ina226@46 {
						compatible = "ti,ina226";
						reg = <0x46>;
						shunt-resistor = <0x1388>;
					};

					ina226@47 {
						compatible = "ti,ina226";
						reg = <0x47>;
						shunt-resistor = <0x1388>;
					};
				};

				i2c@2 {
					#address-cells = <0x01>;
					#size-cells = <0x00>;
					reg = <0x02>;

					max15301@a {
						compatible = "maxim,max15301";
						reg = <0x0a>;
					};

					max15303@b {
						compatible = "maxim,max15303";
						reg = <0x0b>;
					};

					max15303@10 {
						compatible = "maxim,max15303";
						reg = <0x10>;
					};

					max15301@13 {
						compatible = "maxim,max15301";
						reg = <0x13>;
					};

					max15303@14 {
						compatible = "maxim,max15303";
						reg = <0x14>;
					};

					max15303@15 {
						compatible = "maxim,max15303";
						reg = <0x15>;
					};

					max15303@16 {
						compatible = "maxim,max15303";
						reg = <0x16>;
					};

					max15303@17 {
						compatible = "maxim,max15303";
						reg = <0x17>;
					};

					max15301@18 {
						compatible = "maxim,max15301";
						reg = <0x18>;
					};

					max15303@1a {
						compatible = "maxim,max15303";
						reg = <0x1a>;
					};

					max15303@1d {
						compatible = "maxim,max15303";
						reg = <0x1d>;
					};

					max20751@72 {
						compatible = "maxim,max20751";
						reg = <0x72>;
					};

					max20751@73 {
						compatible = "maxim,max20751";
						reg = <0x73>;
					};

					max15303@1b {
						compatible = "maxim,max15303";
						reg = <0x1b>;
					};
				};
			};
		};

		i2c@ff030000 {
			compatible = "cdns,i2c-r1p14\0cdns,i2c-r1p10";
			status = "okay";
			interrupt-parent = <0x04>;
			interrupts = <0x00 0x12 0x04>;
			reg = <0x00 0xff030000 0x00 0x1000>;
			#address-cells = <0x01>;
			#size-cells = <0x00>;
			power-domains = <0x1b>;
			clocks = <0x03 0x3e>;
			clock-frequency = <0x61a80>;
			pinctrl-names = "default\0gpio";
			pinctrl-0 = <0x1c>;
			pinctrl-1 = <0x1d>;
			scl-gpios = <0x1a 0x10 0x00>;
			sda-gpios = <0x1a 0x11 0x00>;

			i2c-mux@74 {
				compatible = "nxp,pca9548";
				#address-cells = <0x01>;
				#size-cells = <0x00>;
				reg = <0x74>;

				i2c@0 {
					#address-cells = <0x01>;
					#size-cells = <0x00>;
					reg = <0x00>;

					eeprom@54 {
						compatible = "atmel,24c08";
						reg = <0x54>;
						#address-cells = <0x01>;
						#size-cells = <0x01>;

						board-sn@0 {
							reg = <0x00 0x14>;
						};

						eth-mac@20 {
							reg = <0x20 0x06>;
						};

						board-name@d0 {
							reg = <0xd0 0x06>;
						};

						board-revision@e0 {
							reg = <0xe0 0x03>;
						};
					};
				};

				i2c@1 {
					#address-cells = <0x01>;
					#size-cells = <0x00>;
					reg = <0x01>;

					clock-generator@36 {
						compatible = "silabs,si5341";
						reg = <0x36>;
					};
				};

				i2c@2 {
					#address-cells = <0x01>;
					#size-cells = <0x00>;
					reg = <0x02>;

					clock-generator@5d {
						#clock-cells = <0x00>;
						compatible = "silabs,si570";
						reg = <0x5d>;
						temperature-stability = <0x32>;
						factory-fout = <0x11e1a300>;
						clock-frequency = <0x11e1a300>;
						clock-output-names = "si570_user";
					};
				};

				i2c@3 {
					#address-cells = <0x01>;
					#size-cells = <0x00>;
					reg = <0x03>;

					clock-generator@5d {
						#clock-cells = <0x00>;
						compatible = "silabs,si570";
						reg = <0x5d>;
						temperature-stability = <0x32>;
						factory-fout = <0x9502f90>;
						clock-frequency = <0x8d9ee20>;
						clock-output-names = "si570_mgt";
					};
				};

				i2c@4 {
					#address-cells = <0x01>;
					#size-cells = <0x00>;
					reg = <0x04>;

					clock-generator@69 {
						compatible = "silabs,si5328";
						reg = <0x69>;
					};
				};
			};

			i2c-mux@75 {
				compatible = "nxp,pca9548";
				#address-cells = <0x01>;
				#size-cells = <0x00>;
				reg = <0x75>;

				i2c@0 {
					#address-cells = <0x01>;
					#size-cells = <0x00>;
					reg = <0x00>;
				};

				i2c@1 {
					#address-cells = <0x01>;
					#size-cells = <0x00>;
					reg = <0x01>;
				};

				i2c@2 {
					#address-cells = <0x01>;
					#size-cells = <0x00>;
					reg = <0x02>;
				};

				i2c@3 {
					#address-cells = <0x01>;
					#size-cells = <0x00>;
					reg = <0x03>;
				};

				i2c@4 {
					#address-cells = <0x01>;
					#size-cells = <0x00>;
					reg = <0x04>;
				};

				i2c@5 {
					#address-cells = <0x01>;
					#size-cells = <0x00>;
					reg = <0x05>;
				};

				i2c@6 {
					#address-cells = <0x01>;
					#size-cells = <0x00>;
					reg = <0x06>;
				};

				i2c@7 {
					#address-cells = <0x01>;
					#size-cells = <0x00>;
					reg = <0x07>;
				};
			};
		};

		memory-controller@ff960000 {
			compatible = "xlnx,zynqmp-ocmc-1.0";
			reg = <0x00 0xff960000 0x00 0x1000>;
			interrupt-parent = <0x04>;
			interrupts = <0x00 0x0a 0x04>;
		};

		perf-monitor@ffa00000 {
			compatible = "xlnx,axi-perf-monitor";
			reg = <0x00 0xffa00000 0x00 0x10000>;
			interrupts = <0x00 0x19 0x04>;
			interrupt-parent = <0x04>;
			xlnx,enable-profile = <0x00>;
			xlnx,enable-trace = <0x00>;
			xlnx,num-monitor-slots = <0x04>;
			xlnx,enable-event-count = <0x01>;
			xlnx,enable-event-log = <0x01>;
			xlnx,have-sampled-metric-cnt = <0x01>;
			xlnx,num-of-counters = <0x08>;
			xlnx,metric-count-width = <0x20>;
			xlnx,metrics-sample-count-width = <0x20>;
			xlnx,global-count-width = <0x20>;
			xlnx,metric-count-scale = <0x01>;
			clocks = <0x03 0x1f>;
		};

		pcie@fd0e0000 {
			compatible = "xlnx,nwl-pcie-2.11";
			status = "okay";
			#address-cells = <0x03>;
			#size-cells = <0x02>;
			#interrupt-cells = <0x01>;
			msi-controller;
			device_type = "pci";
			interrupt-parent = <0x04>;
			interrupts = <0x00 0x76 0x04 0x00 0x75 0x04 0x00 0x74 0x04 0x00 0x73 0x04 0x00 0x72 0x04>;
			interrupt-names = "misc\0dummy\0intx\0msi1\0msi0";
			msi-parent = <0x1e>;
			reg = <0x00 0xfd0e0000 0x00 0x1000 0x00 0xfd480000 0x00 0x1000 0x80 0x00 0x00 0x1000000>;
			reg-names = "breg\0pcireg\0cfg";
			ranges = <0x2000000 0x00 0xe0000000 0x00 0xe0000000 0x00 0x10000000 0x43000000 0x06 0x00 0x06 0x00 0x02 0x00>;
			bus-range = <0x00 0xff>;
			interrupt-map-mask = <0x00 0x00 0x00 0x07>;
			interrupt-map = <0x00 0x00 0x00 0x01 0x1f 0x01 0x00 0x00 0x00 0x02 0x1f 0x02 0x00 0x00 0x00 0x03 0x1f 0x03 0x00 0x00 0x00 0x04 0x1f 0x04>;
			power-domains = <0x20>;
			clocks = <0x03 0x17>;
			linux,phandle = <0x1e>;
			phandle = <0x1e>;

			legacy-interrupt-controller {
				interrupt-controller;
				#address-cells = <0x00>;
				#interrupt-cells = <0x01>;
				linux,phandle = <0x1f>;
				phandle = <0x1f>;
			};
		};

		spi@ff0f0000 {
			u-boot,dm-pre-reloc;
			compatible = "xlnx,zynqmp-qspi-1.0";
			status = "okay";
			clock-names = "ref_clk\0pclk";
			interrupts = <0x00 0x0f 0x04>;
			interrupt-parent = <0x04>;
			num-cs = <0x01>;
			reg = <0x00 0xff0f0000 0x00 0x1000 0x00 0xc0000000 0x00 0x8000000>;
			#address-cells = <0x01>;
			#size-cells = <0x00>;
			#stream-id-cells = <0x01>;
			iommus = <0x0a 0x873>;
			power-domains = <0x21>;
			clocks = <0x03 0x35 0x03 0x1f>;
			is-dual = <0x01>;

			flash@0 {
				compatible = "m25p80\0spi-flash";
				#address-cells = <0x01>;
				#size-cells = <0x01>;
				reg = <0x00>;
				spi-tx-bus-width = <0x01>;
				spi-rx-bus-width = <0x04>;
				spi-max-frequency = <0x66ff300>;

				partition@qspi-fsbl-uboot {
					label = "qspi-fsbl-uboot";
					reg = <0x00 0x100000>;
				};

				partition@qspi-linux {
					label = "qspi-linux";
					reg = <0x100000 0x500000>;
				};

				partition@qspi-device-tree {
					label = "qspi-device-tree";
					reg = <0x600000 0x20000>;
				};

				partition@qspi-rootfs {
					label = "qspi-rootfs";
					reg = <0x620000 0x5e0000>;
				};
			};
		};

		rtc@ffa60000 {
			compatible = "xlnx,zynqmp-rtc";
			status = "okay";
			reg = <0x00 0xffa60000 0x00 0x100>;
			interrupt-parent = <0x04>;
			interrupts = <0x00 0x1a 0x04 0x00 0x1b 0x04>;
			interrupt-names = "alarm\0sec";
			calibration = <0x8000>;
		};

		zynqmp_phy@fd400000 {
			compatible = "xlnx,zynqmp-psgtr-v1.1";
			status = "okay";
			reg = <0x00 0xfd400000 0x00 0x40000 0x00 0xfd3d0000 0x00 0x1000>;
			reg-names = "serdes\0siou";
			nvmem-cells = <0x22>;
			nvmem-cell-names = "soc_revision";
			resets = <0x23 0x10 0x23 0x3b 0x23 0x3c 0x23 0x3d 0x23 0x3e 0x23 0x3f 0x23 0x40 0x23 0x03 0x23 0x1d 0x23 0x1e 0x23 0x1f 0x23 0x20>;
			reset-names = "sata_rst\0usb0_crst\0usb1_crst\0usb0_hibrst\0usb1_hibrst\0usb0_apbrst\0usb1_apbrst\0dp_rst\0gem0_rst\0gem1_rst\0gem2_rst\0gem3_rst";

			lane0 {
				#phy-cells = <0x04>;
			};

			lane1 {
				#phy-cells = <0x04>;
				linux,phandle = <0x3b>;
				phandle = <0x3b>;
			};

			lane2 {
				#phy-cells = <0x04>;
				linux,phandle = <0x37>;
				phandle = <0x37>;
			};

			lane3 {
				#phy-cells = <0x04>;
				linux,phandle = <0x25>;
				phandle = <0x25>;
			};
		};

		ahci@fd0c0000 {
			compatible = "ceva,ahci-1v84";
			status = "okay";
			reg = <0x00 0xfd0c0000 0x00 0x2000>;
			interrupt-parent = <0x04>;
			interrupts = <0x00 0x85 0x04>;
			power-domains = <0x24>;
			#stream-id-cells = <0x04>;
			clocks = <0x03 0x16>;
			ceva,p0-cominit-params = <0x18401828>;
			ceva,p0-comwake-params = <0x614080e>;
			ceva,p0-burst-params = <0x13084a06>;
			ceva,p0-retry-params = <0x96a43ffc>;
			ceva,p1-cominit-params = <0x18401828>;
			ceva,p1-comwake-params = <0x614080e>;
			ceva,p1-burst-params = <0x13084a06>;
			ceva,p1-retry-params = <0x96a43ffc>;
			phy-names = "sata-phy";
			phys = <0x25 0x01 0x01 0x01 0x7735940>;
		};

		mmc@ff160000 {
			u-boot,dm-pre-reloc;
			compatible = "xlnx,zynqmp-8.9a\0arasan,sdhci-8.9a";
			status = "disabled";
			interrupt-parent = <0x04>;
			interrupts = <0x00 0x30 0x04>;
			reg = <0x00 0xff160000 0x00 0x1000>;
			clock-names = "clk_xin\0clk_ahb";
			xlnx,device_id = <0x00>;
			#stream-id-cells = <0x01>;
			iommus = <0x0a 0x870>;
			power-domains = <0x26>;
			nvmem-cells = <0x22>;
			nvmem-cell-names = "soc_revision";
			broken-mmc-highspeed;
			clocks = <0x03 0x36 0x03 0x1f>;
		};

		mmc@ff170000 {
			u-boot,dm-pre-reloc;
			compatible = "xlnx,zynqmp-8.9a\0arasan,sdhci-8.9a";
			status = "okay";
			interrupt-parent = <0x04>;
			interrupts = <0x00 0x31 0x04>;
			reg = <0x00 0xff170000 0x00 0x1000>;
			clock-names = "clk_xin\0clk_ahb";
			xlnx,device_id = <0x01>;
			#stream-id-cells = <0x01>;
			iommus = <0x0a 0x871>;
			power-domains = <0x27>;
			nvmem-cells = <0x22>;
			nvmem-cell-names = "soc_revision";
			broken-mmc-highspeed;
			clocks = <0x03 0x37 0x03 0x1f>;
			pinctrl-names = "default";
			pinctrl-0 = <0x28>;
			no-1-8-v;
			xlnx,mio_bank = <0x01>;
		};

		spi@ff040000 {
			compatible = "cdns,spi-r1p6";
			status = "okay";
			interrupt-parent = <0x04>;
			interrupts = <0x00 0x13 0x04>;
			reg = <0x00 0xff040000 0x00 0x1000>;
			clock-names = "ref_clk\0pclk";
			#address-cells = <0x01>;
			#size-cells = <0x00>;
			power-domains = <0x29>;
			clocks = <0x03 0x3a 0x03 0x1f>;

			ad9694@1 {
				#address-cells = <0x01>;
				#size-cells = <0x00>;
				#clock-cells = <0x01>;
				compatible = "adi,ad9694";
				reg = <0x00>;
				spi-max-frequency = <0x17d7840>;
				clocks = <0x2a 0x2b>;
				clock-names = "jesd_adc_clk\0adc_clk";
				fastdetect-a-gpios = <0x1a 0x70 0x00>;
				fastdetect-b-gpios = <0x1a 0x71 0x00>;
				fastdetect-c-gpios = <0x1a 0x72 0x00>;
				fastdetect-d-gpios = <0x1a 0x73 0x00>;
				powerdown-gpios = <0x1a 0x74 0x01>;
				linux,phandle = <0x48>;
				phandle = <0x48>;
			};
		};

		spi@ff050000 {
			compatible = "cdns,spi-r1p6";
			status = "disabled";
			interrupt-parent = <0x04>;
			interrupts = <0x00 0x14 0x04>;
			reg = <0x00 0xff050000 0x00 0x1000>;
			clock-names = "ref_clk\0pclk";
			#address-cells = <0x01>;
			#size-cells = <0x00>;
			power-domains = <0x2c>;
			clocks = <0x03 0x3b 0x03 0x1f>;
		};

		timer@ff110000 {
			compatible = "cdns,ttc";
			status = "disabled";
			interrupt-parent = <0x04>;
			interrupts = <0x00 0x24 0x04 0x00 0x25 0x04 0x00 0x26 0x04>;
			reg = <0x00 0xff110000 0x00 0x1000>;
			timer-width = <0x20>;
			power-domains = <0x2d>;
			clocks = <0x03 0x1f>;
		};

		timer@ff120000 {
			compatible = "cdns,ttc";
			status = "disabled";
			interrupt-parent = <0x04>;
			interrupts = <0x00 0x27 0x04 0x00 0x28 0x04 0x00 0x29 0x04>;
			reg = <0x00 0xff120000 0x00 0x1000>;
			timer-width = <0x20>;
			power-domains = <0x2e>;
			clocks = <0x03 0x1f>;
		};

		timer@ff130000 {
			compatible = "cdns,ttc";
			status = "disabled";
			interrupt-parent = <0x04>;
			interrupts = <0x00 0x2a 0x04 0x00 0x2b 0x04 0x00 0x2c 0x04>;
			reg = <0x00 0xff130000 0x00 0x1000>;
			timer-width = <0x20>;
			power-domains = <0x2f>;
			clocks = <0x03 0x1f>;
		};

		timer@ff140000 {
			compatible = "cdns,ttc";
			status = "disabled";
			interrupt-parent = <0x04>;
			interrupts = <0x00 0x2d 0x04 0x00 0x2e 0x04 0x00 0x2f 0x04>;
			reg = <0x00 0xff140000 0x00 0x1000>;
			timer-width = <0x20>;
			power-domains = <0x30>;
			clocks = <0x03 0x1f>;
		};

		serial@ff000000 {
			u-boot,dm-pre-reloc;
			compatible = "cdns,uart-r1p12\0xlnx,xuartps";
			status = "okay";
			interrupt-parent = <0x04>;
			interrupts = <0x00 0x15 0x04>;
			reg = <0x00 0xff000000 0x00 0x1000>;
			clock-names = "uart_clk\0pclk";
			power-domains = <0x31>;
			clocks = <0x03 0x38 0x03 0x1f>;
			pinctrl-names = "default";
			pinctrl-0 = <0x32>;
		};

		serial@ff010000 {
			u-boot,dm-pre-reloc;
			compatible = "cdns,uart-r1p12\0xlnx,xuartps";
			status = "okay";
			interrupt-parent = <0x04>;
			interrupts = <0x00 0x16 0x04>;
			reg = <0x00 0xff010000 0x00 0x1000>;
			clock-names = "uart_clk\0pclk";
			power-domains = <0x33>;
			clocks = <0x03 0x39 0x03 0x1f>;
			pinctrl-names = "default";
			pinctrl-0 = <0x34>;
		};

		usb0@ff9d0000 {
			#address-cells = <0x02>;
			#size-cells = <0x02>;
			status = "okay";
			compatible = "xlnx,zynqmp-dwc3";
			reg = <0x00 0xff9d0000 0x00 0x100>;
			clock-names = "bus_clk\0ref_clk";
			power-domains = <0x35>;
			ranges;
			nvmem-cells = <0x22>;
			nvmem-cell-names = "soc_revision";
			clocks = <0x03 0x20 0x03 0x22>;
			pinctrl-names = "default";
			pinctrl-0 = <0x36>;

			dwc3@fe200000 {
				compatible = "snps,dwc3";
				status = "okay";
				reg = <0x00 0xfe200000 0x00 0x40000>;
				interrupt-parent = <0x04>;
				interrupts = <0x00 0x41 0x04 0x00 0x45 0x04 0x00 0x4b 0x04>;
				#stream-id-cells = <0x01>;
				iommus = <0x0a 0x860>;
				snps,quirk-frame-length-adjustment = <0x20>;
				snps,refclk_fladj;
				snps,enable_guctl1_resume_quirk;
				snps,enable_guctl1_ipd_quirk;
				snps,xhci-stream-quirk;
				dr_mode = "host";
				snps,usb3_lpm_capable;
				phy-names = "usb3-phy";
				phys = <0x37 0x04 0x00 0x02 0x18cba80>;
				maximum-speed = "super-speed";
			};
		};

		usb1@ff9e0000 {
			#address-cells = <0x02>;
			#size-cells = <0x02>;
			status = "disabled";
			compatible = "xlnx,zynqmp-dwc3";
			reg = <0x00 0xff9e0000 0x00 0x100>;
			clock-names = "bus_clk\0ref_clk";
			power-domains = <0x38>;
			ranges;
			nvmem-cells = <0x22>;
			nvmem-cell-names = "soc_revision";
			clocks = <0x03 0x21 0x03 0x22>;

			dwc3@fe300000 {
				compatible = "snps,dwc3";
				status = "disabled";
				reg = <0x00 0xfe300000 0x00 0x40000>;
				interrupt-parent = <0x04>;
				interrupts = <0x00 0x46 0x04 0x00 0x4a 0x04 0x00 0x4c 0x04>;
				#stream-id-cells = <0x01>;
				iommus = <0x0a 0x861>;
				snps,quirk-frame-length-adjustment = <0x20>;
				snps,refclk_fladj;
				snps,enable_guctl1_resume_quirk;
				snps,enable_guctl1_ipd_quirk;
				snps,xhci-stream-quirk;
			};
		};

		watchdog@fd4d0000 {
			compatible = "cdns,wdt-r1p2";
			status = "okay";
			interrupt-parent = <0x04>;
			interrupts = <0x00 0x71 0x01>;
			reg = <0x00 0xfd4d0000 0x00 0x1000>;
			timeout-sec = <0x3c>;
			reset-on-timeout;
			clocks = <0x03 0x4b>;
		};

		watchdog@ff150000 {
			compatible = "cdns,wdt-r1p2";
			status = "disabled";
			interrupt-parent = <0x04>;
			interrupts = <0x00 0x34 0x01>;
			reg = <0x00 0xff150000 0x00 0x1000>;
			timeout-sec = <0x0a>;
			clocks = <0x03 0x4b>;
		};

		ams@ffa50000 {
			compatible = "xlnx,zynqmp-ams";
			status = "okay";
			interrupt-parent = <0x04>;
			interrupts = <0x00 0x38 0x04>;
			interrupt-names = "ams-irq";
			reg = <0x00 0xffa50000 0x00 0x800>;
			reg-names = "ams-base";
			#address-cells = <0x02>;
			#size-cells = <0x02>;
			#io-channel-cells = <0x01>;
			ranges;
			clocks = <0x03 0x46>;

			ams_ps@ffa50800 {
				compatible = "xlnx,zynqmp-ams-ps";
				status = "okay";
				reg = <0x00 0xffa50800 0x00 0x400>;
			};

			ams_pl@ffa50c00 {
				compatible = "xlnx,zynqmp-ams-pl";
				status = "okay";
				reg = <0x00 0xffa50c00 0x00 0x400>;
			};
		};

		dma@fd4c0000 {
			compatible = "xlnx,dpdma";
			status = "okay";
			reg = <0x00 0xfd4c0000 0x00 0x1000>;
			interrupts = <0x00 0x7a 0x04>;
			interrupt-parent = <0x04>;
			clock-names = "axi_clk";
			power-domains = <0x39>;
			dma-channels = <0x06>;
			#dma-cells = <0x01>;
			clocks = <0x03 0x14>;
			linux,phandle = <0x3c>;
			phandle = <0x3c>;

			dma-video0channel {
				compatible = "xlnx,video0";
			};

			dma-video1channel {
				compatible = "xlnx,video1";
			};

			dma-video2channel {
				compatible = "xlnx,video2";
			};

			dma-graphicschannel {
				compatible = "xlnx,graphics";
			};

			dma-audio0channel {
				compatible = "xlnx,audio0";
			};

			dma-audio1channel {
				compatible = "xlnx,audio1";
			};
		};

		zynqmp-display@fd4a0000 {
			compatible = "xlnx,zynqmp-dpsub-1.7";
			status = "okay";
			reg = <0x00 0xfd4a0000 0x00 0x1000 0x00 0xfd4aa000 0x00 0x1000 0x00 0xfd4ab000 0x00 0x1000 0x00 0xfd4ac000 0x00 0x1000>;
			reg-names = "dp\0blend\0av_buf\0aud";
			interrupts = <0x00 0x77 0x04>;
			interrupt-parent = <0x04>;
			clock-names = "dp_apb_clk\0dp_aud_clk\0dp_vtc_pixel_clk_in";
			power-domains = <0x39>;
			clocks = <0x3a 0x03 0x11 0x03 0x10>;
			phy-names = "dp-phy0";
			phys = <0x3b 0x05 0x00 0x03 0x19bfcc0>;

			vid-layer {
				dma-names = "vid0\0vid1\0vid2";
				dmas = <0x3c 0x00 0x3c 0x01 0x3c 0x02>;
			};

			gfx-layer {
				dma-names = "gfx0";
				dmas = <0x3c 0x03>;
			};

			i2c-bus {
			};

			zynqmp_dp_snd_codec0 {
				compatible = "xlnx,dp-snd-codec";
				clock-names = "aud_clk";
				clocks = <0x03 0x11>;
				status = "okay";
				linux,phandle = <0x3f>;
				phandle = <0x3f>;
			};

			zynqmp_dp_snd_pcm0 {
				compatible = "xlnx,dp-snd-pcm";
				dmas = <0x3c 0x04>;
				dma-names = "tx";
				status = "okay";
				linux,phandle = <0x3d>;
				phandle = <0x3d>;
			};

			zynqmp_dp_snd_pcm1 {
				compatible = "xlnx,dp-snd-pcm";
				dmas = <0x3c 0x05>;
				dma-names = "tx";
				status = "okay";
				linux,phandle = <0x3e>;
				phandle = <0x3e>;
			};

			zynqmp_dp_snd_card {
				compatible = "xlnx,dp-snd-card";
				xlnx,dp-snd-pcm = <0x3d 0x3e>;
				xlnx,dp-snd-codec = <0x3f>;
				status = "okay";
			};
		};
	};

	fclk0 {
		status = "disabled";
		compatible = "xlnx,fclk";
		clocks = <0x03 0x47>;
	};

	fclk1 {
		status = "disabled";
		compatible = "xlnx,fclk";
		clocks = <0x03 0x48>;
	};

	fclk2 {
		status = "disabled";
		compatible = "xlnx,fclk";
		clocks = <0x03 0x49>;
	};

	fclk3 {
		status = "disabled";
		compatible = "xlnx,fclk";
		clocks = <0x03 0x4a>;
	};

	pss_ref_clk {
		u-boot,dm-pre-reloc;
		compatible = "fixed-clock";
		#clock-cells = <0x00>;
		clock-frequency = <0x1fca055>;
		linux,phandle = <0x40>;
		phandle = <0x40>;
	};

	video_clk {
		u-boot,dm-pre-reloc;
		compatible = "fixed-clock";
		#clock-cells = <0x00>;
		clock-frequency = <0x19bfcc0>;
		linux,phandle = <0x41>;
		phandle = <0x41>;
	};

	pss_alt_ref_clk {
		u-boot,dm-pre-reloc;
		compatible = "fixed-clock";
		#clock-cells = <0x00>;
		clock-frequency = <0x00>;
		linux,phandle = <0x42>;
		phandle = <0x42>;
	};

	gt_crx_ref_clk {
		u-boot,dm-pre-reloc;
		compatible = "fixed-clock";
		#clock-cells = <0x00>;
		clock-frequency = <0x66ff300>;
		linux,phandle = <0x44>;
		phandle = <0x44>;
	};

	aux_ref_clk {
		u-boot,dm-pre-reloc;
		compatible = "fixed-clock";
		#clock-cells = <0x00>;
		clock-frequency = <0x19bfcc0>;
		linux,phandle = <0x43>;
		phandle = <0x43>;
	};

	clk {
		u-boot,dm-pre-reloc;
		#clock-cells = <0x01>;
		compatible = "xlnx,zynqmp-clk";
		clocks = <0x40 0x41 0x42 0x43 0x44>;
		clock-names = "pss_ref_clk\0video_clk\0pss_alt_ref_clk\0aux_ref_clk\0gt_crx_ref_clk";
		linux,phandle = <0x03>;
		phandle = <0x03>;
	};

	dp_aclk {
		compatible = "fixed-clock";
		#clock-cells = <0x00>;
		clock-frequency = <0x5f5e100>;
		clock-accuracy = <0x64>;
		linux,phandle = <0x3a>;
		phandle = <0x3a>;
	};

	aliases {
		ethernet0 = "/amba/ethernet@ff0e0000";
		gpio0 = "/amba/gpio@ff0a0000";
		i2c0 = "/amba/i2c@ff020000";
		i2c1 = "/amba/i2c@ff030000";
		mmc0 = "/amba/mmc@ff170000";
		rtc0 = "/amba/rtc@ffa60000";
		serial0 = "/amba/serial@ff000000";
		serial1 = "/amba/serial@ff010000";
		serial2 = "/dcc";
		spi0 = "/amba/spi@ff0f0000";
		usb0 = "/amba/usb0@ff9d0000";
	};

	chosen {
		bootargs = "earlycon";
		stdout-path = "serial0:115200n8";
	};

	memory@0 {
		device_type = "memory";
		reg = <0x00 0x00 0x00 0x80000000 0x08 0x00 0x00 0x80000000>;
	};

	gpio-keys {
		compatible = "gpio-keys";
		autorepeat;

		sw19 {
			label = "sw19";
			gpios = <0x1a 0x16 0x00>;
			linux,code = <0x6c>;
			gpio-key,wakeup;
			autorepeat;
		};
	};

	leds {
		compatible = "gpio-leds";

		heartbeat_led {
			label = "heartbeat";
			gpios = <0x1a 0x17 0x00>;
			linux,default-trigger = "heartbeat";
		};
	};

	fpga-axi@0 {
		interrupt-parent = <0x04>;
		compatible = "simple-bus";
		#address-cells = <0x01>;
		#size-cells = <0x01>;
		ranges = <0x00 0x00 0x00 0xffffffff>;
		
    mil_1553_axi_fifo: axi_fifo_mm_s@43c00000 {
        compatible = "xlnx,axi-fifo-mm-s-4.1";
        interrupt-parent = <0x04>;
        interrupts = <0x00 0x6e 0x04>;
        reg = <0x83c00000 0x10000>;
        xlnx,axi-str-rxd-protocol = "XIL_AXI_STREAM_ETH_DATA";
        xlnx,axi-str-rxd-tdata-width = <0x20>;
        xlnx,axi-str-txc-protocol = "XIL_AXI_STREAM_ETH_CTRL";
        xlnx,axi-str-txc-tdata-width = <0x20>;
        xlnx,axi-str-txd-protocol = "XIL_AXI_STREAM_ETH_DATA";
        xlnx,axi-str-txd-tdata-width = <0x20>;
        xlnx,axis-tdest-width = <0x4>;
        xlnx,axis-tid-width = <0x4>;
        xlnx,axis-tuser-width = <0x4>;
        xlnx,data-interface-type = <0x0>;
        xlnx,has-axis-tdest = <0x0>;
        xlnx,has-axis-tid = <0x0>;
        xlnx,has-axis-tkeep = <0x1>;
        xlnx,has-axis-tstrb = <0x0>;
        xlnx,has-axis-tuser = <0x0>;
        xlnx,rx-fifo-depth = <0x200>;
        xlnx,rx-fifo-pe-threshold = <0x5>;
        xlnx,rx-fifo-pf-threshold = <0x1fb>;
        xlnx,s-axi-id-width = <0x4>;
        xlnx,s-axi4-data-width = <0x20>;
        xlnx,select-xpm = <0x0>;
        xlnx,tx-fifo-depth = <0x200>;
        xlnx,tx-fifo-pe-threshold = <0x5>;
        xlnx,tx-fifo-pf-threshold = <0x1fb>;
        xlnx,use-rx-cut-through = <0x0>;
        xlnx,use-rx-data = <0x1>;
        xlnx,use-tx-ctrl = <0x0>;
        xlnx,use-tx-cut-through = <0x0>;
        xlnx,use-tx-data = <0x1>;
        xlnx,tx-max-pkt-size = <257>; 
        xlnx,rx-min-pkt-size = <255>; 
    };
    
		axi-adxcvr-rx@84a50000 {
			compatible = "adi,axi-adxcvr-1.0";
			reg = <0x84a50000 0x1000>;
			clocks = <0x45>;
			clock-names = "conv";
			#clock-cells = <0x01>;
			clock-output-names = "adc_gt_clk\0rx_out_clk";
			adi,sys-clk-select = <0x03>;
			adi,out-clk-select = <0x02>;
			adi,use-lpm-enable;
			linux,phandle = <0x46>;
			phandle = <0x46>;
		};

		axi-jesd204-rx@84aa0000 {
			compatible = "adi,axi-jesd204-rx-1.0";
			reg = <0x84aa0000 0x1000>;
			interrupts = <0x00 0x6b 0x04>;
			clocks = <0x03 0x47 0x46 0x01 0x46 0x00>;
			clock-names = "s_axi_aclk\0device_clk\0lane_clk";
			adi,octets-per-frame = <0x01>;
			adi,frames-per-multiframe = <0x20>;
			adi,converter-resolution = <0x08>;
			adi,bits-per-sample = <0x08>;
			adi,converters-per-device = <0x02>;
			adi,subclass = <0x00>;
			#clock-cells = <0x00>;
			clock-output-names = "jesd_adc_lane_clk";
			linux,phandle = <0x2a>;
			phandle = <0x2a>;
		};

		rx-dmac@9c400000 {
			compatible = "adi,axi-dmac-1.00.a";
			reg = <0x9c400000 0x10000>;
			#dma-cells = <0x01>;
			interrupts = <0x00 0x6d 0x04>;
			clocks = <0x03 0x47>;
			linux,phandle = <0x47>;
			phandle = <0x47>;

			adi,channels {
				#size-cells = <0x00>;
				#address-cells = <0x01>;

				dma-channel@0 {
					reg = <0x00>;
					adi,source-bus-width = <0x40>;
					adi,source-bus-type = <0x02>;
					adi,destination-bus-width = <0x40>;
					adi,destination-bus-type = <0x00>;
				};
			};
		};

		axi-ad9694-hpc@84a10000 {
			compatible = "adi,axi-ad9694-1.0";
			reg = <0x84a10000 0x10000>;
			dmas = <0x47 0x00>;
			dma-names = "rx";
			spibus-connected = <0x48>;
			adi,axi-additional-channel-available;
		};

		axi-sysid@85000000 {
			compatible = "adi,axi-sysid-1.00.a";
			reg = <0x85000000 0x10000>;
		};
	};

	clocks {

		clock@0 {
			#clock-cells = <0x00>;
			compatible = "fixed-clock";
			clock-frequency = <0x1dcd6500>;
			clock-output-names = "adc_ref_clock";
			linux,phandle = <0x2b>;
			phandle = <0x2b>;
		};

		clock@1 {
			#clock-cells = <0x00>;
			compatible = "fixed-clock";
			clock-frequency = <0xee6b280>;
			clock-output-names = "fpga_ref_clock";
			linux,phandle = <0x45>;
			phandle = <0x45>;
		};

		clock@2 {
			#clock-cells = <0x00>;
			compatible = "fixed-clock";
			clock-frequency = <0x7735940>;
			clock-output-names = "lane_ref_clock";
		};
	};

	regulator-vref-adc {
		compatible = "regulator-fixed";
		regulator-name = "vref-adc";
		regulator-min-microvolt = <0x4c4b40>;
		regulator-max-microvolt = <0x4c4b40>;
		regulator-always-on;
	};
};
